AUTOSAR XML (schema 4-3-0)
package /Compositions
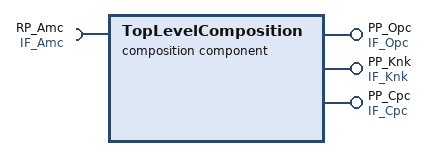
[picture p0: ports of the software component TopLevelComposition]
  composition sw component type TopLevelComposition
    require port RP_Amc: required-interface=IF_Amc
    provide port PP_Opc: provided-interface=IF_Opc
    provide port PP_Knk: provided-interface=IF_Knk
    provide port PP_Cpc: provided-interface=IF_Cpc
    18 x component:
      CPT_Sensors: type=Sensors
      CPT_Fmc: type=Fmc
      CPT_Tqs: type=Tqs
      CPT_Epm: type=Epm
      CPT_Afr: type=Afr
      CPT_Amf: type=Amf
      CPT_Iac: type=Iac
      CPT_Icc: type=Icc
      CPT_Isc: type=Isc
      CPT_Itc: type=Itc
      CPT_Lcc: type=Lcc
      CPT_Opm: type=Opm
      CPT_Stc: type=Stc
      CPT_Actuators: type=Actuators
      CPT_T2t: type=T2t
      CPT_Cc: type=Cc
      CPT_FmcParams: type=FmcParams
      CPT_TqsParams: type=TqsParams
    connect CPT_Sensors.PP_Egas -> CPT_Tqs.RP_Egc
    connect CPT_Epm.PP_Epm -> CPT_Sensors.RP_Epm
    connect CPT_Epm.PP_Epm -> CPT_Tqs.RP_Epm
    connect CPT_Sensors.PP_Ctc -> CPT_Afr.RP_Ctc
    connect CPT_Sensors.PP_Mtc -> CPT_Afr.RP_Mtc
    connect CPT_Epm.PP_Epm -> CPT_Afr.RP_Epm
    connect CPT_Sensors.PP_Ctc -> CPT_Tqs.RP_Ctc
    connect CPT_Epm.PP_Epm -> CPT_Iac.RP_Epm
    connect CPT_Sensors.PP_Mpc -> CPT_Iac.RP_Mpc
    connect CPT_Sensors.PP_Mtc -> CPT_Icc.RP_Mtc
    connect CPT_Isc.PP_Isc -> CPT_Tqs.RP_Isc
    connect CPT_Isc.PP_Isc -> CPT_Iac.RP_Isc
    connect CPT_Epm.PP_Epm -> CPT_Isc.RP_Epm
    connect CPT_Sensors.PP_Mpc -> CPT_Itc.RP_Mpc
    connect CPT_Iac.PP_Iac -> CPT_Itc.RP_Iac
    connect CPT_Isc.PP_Isc -> CPT_Itc.RP_Isc
    connect CPT_Epm.PP_Epm -> CPT_Itc.RP_Epm
    connect CPT_Sensors.PP_Bvc -> CPT_Itc.RP_Bvc
    connect CPT_Afr.PP_Afr -> CPT_Lcc.RP_Afr
    connect CPT_Epm.PP_Epm -> CPT_Lcc.RP_Epm
    connect CPT_Sensors.PP_Mpc -> CPT_Lcc.RP_Mpc
    connect CPT_Isc.PP_Isc -> CPT_Lcc.RP_Isc
    connect CPT_Sensors.PP_Lmc -> CPT_Lcc.RP_Lmc
    connect CPT_Sensors.PP_Eih -> CPT_Opm.RP_Eih
    connect CPT_Sensors.PP_Ctc -> CPT_Stc.RP_Ctc
    connect CPT_Stc.PP_Stc -> CPT_Isc.RP_Stc
    connect CPT_Epm.PP_Epm -> CPT_Stc.RP_Epm
    connect CPT_Opm.PP_Opm -> CPT_Stc.RP_Opm
    connect CPT_Stc.PP_Stc -> CPT_Lcc.RP_Stc
    connect CPT_Stc.PP_Stc -> CPT_Itc.RP_Stc
    connect CPT_Fmc.PP_Fmc -> CPT_Itc.RP_Fmc
    connect CPT_Amf.PP_Amf -> CPT_Afr.RP_Amf
    connect CPT_Sensors.PP_Mpc -> CPT_Amf.RP_Mpc
    connect CPT_Amf.PP_Amf -> CPT_Fmc.RP_Amf
    connect CPT_Sensors.PP_Mtc -> CPT_Amf.RP_Mtc
    connect CPT_Afr.PP_Afr -> CPT_Fmc.RP_Afr
    connect CPT_Epm.PP_Epm -> CPT_Fmc.RP_Epm
    connect CPT_Sensors.PP_Ctc -> CPT_Amf.RP_Ctc
    connect CPT_Lcc.PP_Lcc -> CPT_Fmc.RP_Lcc
    connect CPT_Itc.PP_Itc -> CPT_Fmc.RP_Itc
    connect CPT_Epm.PP_Epm -> CPT_Amf.RP_Epm
    connect CPT_Amf.PP_Amf -> CPT_Tqs.RP_Amf
    connect CPT_Amf.PP_Amf -> CPT_Iac.RP_Amf
    connect CPT_Actuators.PP_Doh -> CPT_Opm.RP_Doh
    connect CPT_Stc.PP_Stc -> CPT_Actuators.RP_Stc
    connect CPT_Actuators.PP_Eoh -> CPT_Opm.RP_Eoh
    connect CPT_Iac.PP_Iac -> CPT_Actuators.RP_Iac
    connect CPT_Icc.PP_Icc -> CPT_Actuators.RP_Icc
    connect CPT_Opm.PP_Opm -> CPT_Actuators.RP_Opm
    connect CPT_Itc.PP_Itc -> CPT_Actuators.RP_Itc
    connect CPT_Sensors.PP_Ctc -> CPT_Actuators.RP_Ctc
    connect CPT_Tqs.PP_Tqs -> CPT_Fmc.RP_Tqs
    connect CPT_Afr.PP_Afr -> CPT_T2t.RP_Afr
    connect CPT_Isc.PP_Isc -> CPT_T2t.RP_Isc
    connect CPT_Tqs.PP_Tqs -> CPT_T2t.RP_Tqs
    connect CPT_T2t.PP_T2t -> CPT_Actuators.RP_T2t
    connect CPT_T2t.PP_T2t -> CPT_Iac.RP_T2t
    connect CPT_Stc.PP_Stc -> CPT_T2t.RP_Stc
    connect CPT_Sensors.PP_Mpc -> CPT_T2t.RP_Mpc
    connect CPT_Epm.PP_Epm -> CPT_T2t.RP_Epm
    connect CPT_Iac.PP_Iac -> CPT_T2t.RP_Iac
    connect CPT_Cc.PP_Cc -> CPT_Stc.RP_Cc
    connect CPT_Cc.PP_Cc -> CPT_Actuators.RP_Cc
    connect CPT_Epm.PP_Epm -> CPT_Cc.RP_Epm
    connect CPT_T2t.PP_T2t -> CPT_Cc.RP_T2t
    connect CPT_Sensors.PP_Kl50 -> CPT_Cc.RP_Kl50
    connect CPT_Icc.PP_Icc -> CPT_Cc.RP_Icc
    connect CPT_Sensors.PP_Egas -> CPT_Cc.RP_Egc
    connect CPT_FmcParams.PP_FmcParams -> CPT_Fmc.RP_FmcParams
    connect CPT_TqsParams.PP_TqsParams -> CPT_Tqs.RP_TqsParams
    connect CPT_Opm.PM_OperatingMode -> CPT_Icc.RM_OperatingMode
    delegate CPT_Amf.RP_Amc <-> outer port RP_Amc
    delegate CPT_Sensors.PP_Opc <-> outer port PP_Opc
    delegate CPT_Sensors.PP_Knk <-> outer port PP_Knk
    delegate CPT_Sensors.PP_Cpc <-> outer port PP_Cpc
    connect CPT_Opm.PM_OperatingMode -> CPT_Actuators.RM_OperatingMode
    connect CPT_Opm.PM_OperatingMode -> CPT_Stc.RM_OperatingMode
package /Compositions/PortInterfaceMappingSets
  port interface mapping set PIMSet_TopLevelComposition
